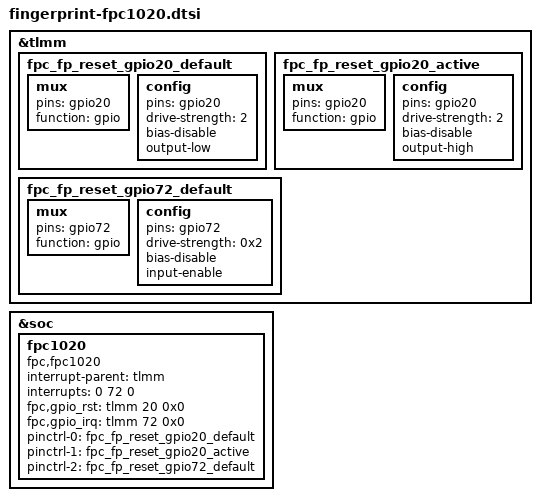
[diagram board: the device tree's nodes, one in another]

&tlmm {
	/* GPIO_20 : FP_RESET_N */
	fpc_fp_reset_gpio20_default: fpc_fp_reset_gpio20_default {
		mux {
			pins = "gpio20";
			function = "gpio";
		};

		config {
			pins = "gpio20";
			drive-strength = <2>;
			bias-disable;
			output-low;
		};
	};

	/* GPIO_20 : FP_RESET_N, state device active*/
	fpc_fp_reset_gpio20_active: fpc_fp_reset_gpio20_active {
		mux {
			pins = "gpio20";
			function = "gpio";
		};

		config {
			pins = "gpio20";
			drive-strength = <2>;
			bias-disable;
			output-high;
		};
	};

	/* GPIO_72 : FP_INT_N */
	fpc_fp_reset_gpio72_default: fpc_fp_reset_gpio72_default {
		mux {
			pins = "gpio72";
			function = "gpio";
		};

		config {
			pins = "gpio72";
			drive-strength = <0x2>;
			bias-disable;
			input-enable;
		};
	};
};

&soc {
	fpc1020 {
			compatible = "fpc,fpc1020";
			status = "okay";
			interrupt-parent = <&tlmm>;
			interrupts = <0 72 0>;
			fpc,gpio_rst = <&tlmm 20 0x0>;
			fpc,gpio_irq = <&tlmm 72 0x0>;

			pinctrl-names = "fpc1020_reset_reset",
			"fpc1020_reset_active",
			"fpc1020_irq_active";

			pinctrl-0 = <&fpc_fp_reset_gpio20_default>;
			pinctrl-1 = <&fpc_fp_reset_gpio20_active>;
			pinctrl-2 = <&fpc_fp_reset_gpio72_default>;
		};
};
